VERSION ""

NS_ :

BS_:

BU_:
VAL_TABLE_ DomainCtrl_EPO 1 "急停拍下" 0 "急停恢复" ;
VAL_TABLE_ EPB_FKDSts 1 "锁死" 0 "释放" ;
VAL_TABLE_ EPB2_FAULT 16 "未知状态" 4 "ECU故障" 2 "左卡钳故障" 1 "右卡钳故障" 0 "无故障" ;
VAL_TABLE_ EPB1_FAULT 16 "未知状态" 8 "通讯故障" 4 "ECU故障" 2 "左卡钳故障" 1 "右卡钳故障" 0 "无故障" ;
VAL_TABLE_ EPB_MRSts 4 "unknown" 3 "Applying" 2 "Releasing" 1 "Applied" 0 "Released" ;
VAL_TABLE_ EPB_MLSts 4 "unknown" 3 "Applying" 2 "Releasing" 1 "Applied" 0 "Released" ;
VAL_TABLE_ EPB_RFRSts 4 "unknown" 3 "Applying" 2 "Releasing" 1 "Applied" 0 "Released" ;
VAL_TABLE_ EPB_LFRSts 4 "unknown" 3 "Applying" 2 "Releasing" 1 "Applied" 0 "Released" ;
VAL_TABLE_ SteeringMode 1 "原地掉头" 0 "阿克曼转向" ;
VAL_TABLE_ EBS2_Fault 1 "故障" 0 "正常" ;
VAL_TABLE_ EBS1_Fault 1 "故障" 0 "正常" ;
VAL_TABLE_ RRMCU_Fault 1 "故障" 0 "正常" ;
VAL_TABLE_ RLMCU_Fault 1 "故障" 0 "正常" ;
VAL_TABLE_ MRMCU_Fault 1 "故障" 0 "正常" ;
VAL_TABLE_ MLMCU_Fault 1 "故障" 0 "正常" ;
VAL_TABLE_ FRMCU_Fault 1 "故障" 0 "正常" ;
VAL_TABLE_ FLMCU_Fault 1 "故障" 0 "正常" ;
VAL_TABLE_ CarStartState 2 "关机" 1 "启动" 0 "未知" ;
VAL_TABLE_ CarSts2 1 "急停状态" 0 "READY" ;
VAL_TABLE_ CarSts1 3 "三级报警" 2 "二级报警" 1 "一级报警" 0 "正常" ;
VAL_TABLE_ YK_F 1 "触发" 0 "未触发" ;
VAL_TABLE_ YK_H 1 "触发" 0 "未触发" ;
VAL_TABLE_ EPOSts 2 "硬线触发" 1 "遥控器触发" 0 "未触发" ;
VAL_TABLE_ Gear 3 "D档" 2 "N档" 1 "倒挡R" 0 "P档" ;
VAL_TABLE_ Drive_Mode 2 "遥控器调试模式" 1 "自动模式（线控）" 0 "手动控制模式（油门踏板+挡位）" ;
VAL_TABLE_ OutLineLamp 1 "打开" 0 "关闭" ;
VAL_TABLE_ AlarmLamp 1 "打开" 0 "关闭" ;
VAL_TABLE_ Car_OFF 1 "关机" 0 "正常" ;
VAL_TABLE_ Horn 1 "打开" 0 "关闭" ;
VAL_TABLE_ FarLamp 1 "打开" 0 "关闭" ;
VAL_TABLE_ TurnLamp 2 "右转向" 1 "左转向" 0 "归位" ;
VAL_TABLE_ DippedLamp 1 "打开" 0 "关闭" ;
VAL_TABLE_ Brake_En 1 "使能" 0 "未使能" ;
VAL_TABLE_ Target_Gear 3 "D档" 2 "N档" 1 "倒挡R" 0 "P档" ;
VAL_TABLE_ IPC_En 1 "使能" 0 "未使能" ;
VAL_TABLE_ Ultrasonic_En 1 "关闭" 0 "开启" ;

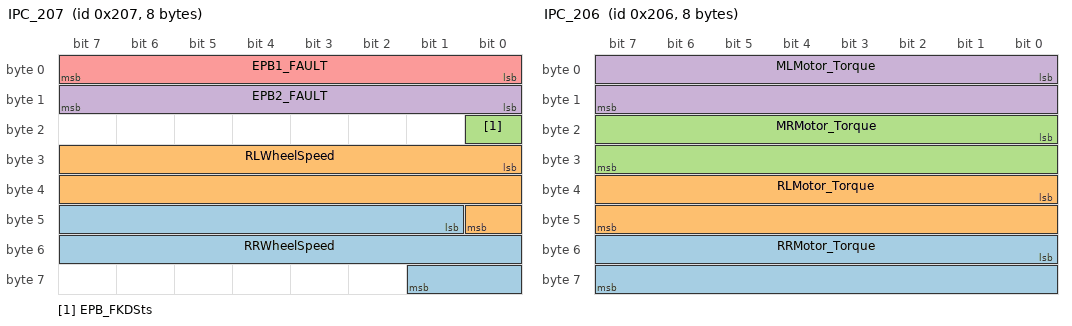
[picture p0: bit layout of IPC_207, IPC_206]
BO_ 519 IPC_207: 8 Vector__XXX
 SG_ RRWheelSpeed : 41|17@1+ (0.01,-655) [-655|655.71] "rpm" Vector__XXX
 SG_ RLWheelSpeed : 24|17@1+ (0.01,-655) [-655|655.71] "rpm" Vector__XXX
 SG_ EPB_FKDSts : 16|1@1+ (1,0) [0|1] "" Vector__XXX
 SG_ EPB2_FAULT : 8|8@1+ (1,0) [0|255] "" Vector__XXX
 SG_ EPB1_FAULT : 0|8@1+ (1,0) [0|255] "" Vector__XXX

BO_ 518 IPC_206: 8 Vector__XXX
 SG_ RRMotor_Torque : 48|16@1+ (0.1,-2000) [-2000|4553.5] "n*m" Vector__XXX
 SG_ RLMotor_Torque : 32|16@1+ (0.1,-2000) [-2000|4553.5] "n*m" Vector__XXX
 SG_ MRMotor_Torque : 16|16@1+ (0.1,-2000) [-2000|4553.5] "n*m" Vector__XXX
 SG_ MLMotor_Torque : 0|16@1+ (0.1,-2000) [-2000|4553.5] "n*m" Vector__XXX

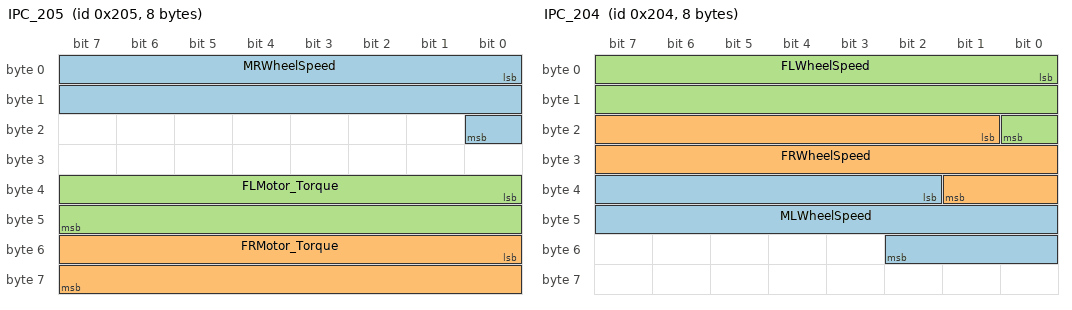
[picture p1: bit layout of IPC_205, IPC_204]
BO_ 517 IPC_205: 8 Vector__XXX
 SG_ MRWheelSpeed : 0|17@1+ (0.01,-655) [-655|655.71] "rpm" Vector__XXX
 SG_ FRMotor_Torque : 48|16@1+ (0.1,-2000) [-2000|4553.5] "n*m" Vector__XXX
 SG_ FLMotor_Torque : 32|16@1+ (0.1,-2000) [-2000|4553.5] "n*m" Vector__XXX

BO_ 516 IPC_204: 8 Vector__XXX
 SG_ MLWheelSpeed : 34|17@1+ (0.01,-655) [-655|655.71] "rpm" Vector__XXX
 SG_ FRWheelSpeed : 17|17@1+ (0.01,-655) [-655|655.71] "rpm" Vector__XXX
 SG_ FLWheelSpeed : 0|17@1+ (0.01,-655) [-655|655.71] "rpm" Vector__XXX

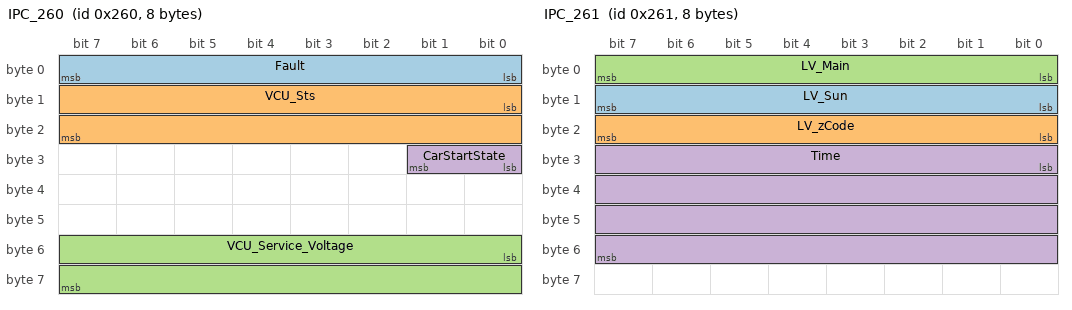
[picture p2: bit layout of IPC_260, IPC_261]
BO_ 608 IPC_260: 8 Vector__XXX
 SG_ Fault : 0|8@1+ (1,0) [0|255] "" Vector__XXX
 SG_ VCU_Sts : 8|16@1+ (1,0) [0|65535] "" Vector__XXX
 SG_ VCU_Service_Voltage : 48|16@1+ (1,0) [0|65535] "mv" Vector__XXX
 SG_ CarStartState : 24|2@1+ (1,0) [0|3] "" Vector__XXX

BO_ 609 IPC_261: 8 Vector__XXX
 SG_ LV_Sun : 8|8@1+ (1,0) [0|255] "" Vector__XXX
 SG_ LV_zCode : 16|8@1+ (1,0) [0|255] "" Vector__XXX
 SG_ LV_Main : 0|8@1+ (1,0) [0|255] "" Vector__XXX
 SG_ Time : 24|32@1+ (1,0) [0|4294967295] "" Vector__XXX

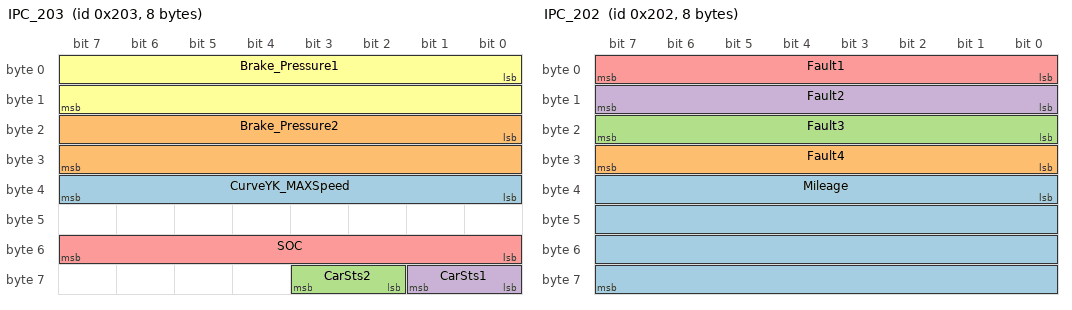
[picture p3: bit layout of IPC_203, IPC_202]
BO_ 515 IPC_203: 8 Vector__XXX
 SG_ CurveYK_MAXSpeed : 32|8@1+ (1,0) [0|255] "km/h" Vector__XXX
 SG_ Brake_Pressure2 : 16|16@1+ (0.05,0) [0|10] "Mpa" Vector__XXX
 SG_ CarSts2 : 58|2@1+ (1,0) [0|3] "" Vector__XXX
 SG_ CarSts1 : 56|2@1+ (1,0) [0|3] "" Vector__XXX
 SG_ SOC : 48|8@1+ (1,0) [0|255] "%" Vector__XXX
 SG_ Brake_Pressure1 : 0|16@1+ (0.05,0) [0|10] "MPa" Vector__XXX

BO_ 514 IPC_202: 8 Vector__XXX
 SG_ Mileage : 32|32@1+ (0.1,0) [0|999999.9] "km" Vector__XXX
 SG_ Fault4 : 24|8@1+ (1,0) [0|255] "" Vector__XXX
 SG_ Fault3 : 16|8@1+ (1,0) [0|255] "" Vector__XXX
 SG_ Fault2 : 8|8@1+ (1,0) [0|255] "" Vector__XXX
 SG_ Fault1 : 0|8@1+ (1,0) [0|255] "" Vector__XXX

BO_ 513 IPC_201: 8 Vector__XXX
 SG_ EPB_MRSts : 60|4@1+ (1,0) [0|15] "" Vector__XXX
 SG_ EPB_MLSts : 56|4@1+ (1,0) [0|15] "" Vector__XXX
 SG_ EPB_RFRSts : 52|4@1+ (1,0) [0|15] "" Vector__XXX
 SG_ EPB_LFRSts : 48|4@1+ (1,0) [0|15] "" Vector__XXX
 SG_ EBS2_Fault : 31|1@1+ (1,0) [0|1] "" Vector__XXX
 SG_ EBS1_Fault : 30|1@1+ (1,0) [0|1] "" Vector__XXX
 SG_ RRMCU_Fault : 29|1@1+ (1,0) [0|1] "" Vector__XXX
 SG_ RLMCU_Fault : 28|1@1+ (1,0) [0|1] "" Vector__XXX
 SG_ MRMCU_Fault : 27|1@1+ (1,0) [0|1] "" Vector__XXX
 SG_ MLMCU_Fault : 26|1@1+ (1,0) [0|1] "" Vector__XXX
 SG_ FRMCU_Fault : 25|1@1+ (1,0) [0|1] "" Vector__XXX
 SG_ FLMCU_Fatus : 24|1@1+ (1,0) [0|1] "" Vector__XXX
 SG_ YK_H : 6|1@1+ (1,0) [0|1] "" Vector__XXX
 SG_ YK_F : 7|1@1+ (1,0) [0|1] "" Vector__XXX
 SG_ Car_Speed : 32|16@1+ (0.1,0) [0|6553.5] "km/h" Vector__XXX
 SG_ Gear : 2|2@1+ (1,0) [0|3] "" Vector__XXX
 SG_ EPOSts : 4|2@1+ (1,0) [0|3] "" Vector__XXX
 SG_ Drive_Mode : 0|2@1+ (1,0) [0|3] "" Vector__XXX
 SG_ Angle : 8|16@1- (1,0) [-32768|32767] "°" Vector__XXX

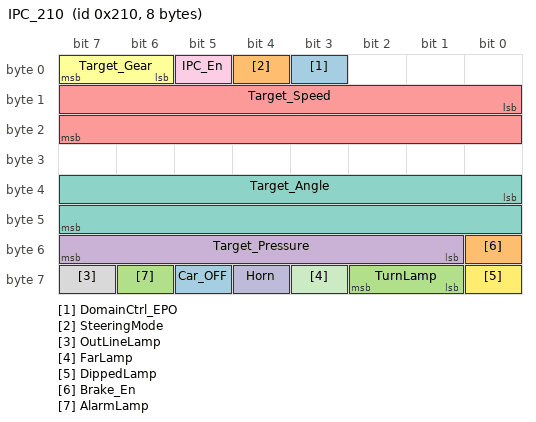
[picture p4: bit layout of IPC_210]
BO_ 528 IPC_210: 8 Vector__XXX
 SG_ DomainCtrl_EPO : 3|1@1+ (1,0) [0|1] "" Vector__XXX
 SG_ SteeringMode : 4|1@1+ (1,0) [0|1] "" Vector__XXX
 SG_ TurnLamp : 57|2@1+ (1,0) [0|3] "" Vector__XXX
 SG_ Target_Pressure : 49|7@1+ (0.1,0) [0|6] "Mpa" Vector__XXX
 SG_ Target_Speed : 8|16@1+ (0.1,0) [0|6553.5] "km/h" Vector__XXX
 SG_ Target_Gear : 6|2@1+ (1,0) [0|3] "" Vector__XXX
 SG_ Target_Angle : 32|16@1- (1,0) [-32768|32767] "°" Vector__XXX
 SG_ OutLineLamp : 63|1@1+ (1,0) [0|1] "" Vector__XXX
 SG_ IPC_En : 5|1@1+ (1,0) [0|1] "" Vector__XXX
 SG_ Horn : 60|1@1+ (1,0) [0|1] "" Vector__XXX
 SG_ FarLamp : 59|1@1+ (1,0) [0|1] "" Vector__XXX
 SG_ DippedLamp : 56|1@1+ (1,0) [0|1] "" Vector__XXX
 SG_ Car_OFF : 61|1@1+ (1,0) [0|1] "" Vector__XXX
 SG_ Brake_En : 48|1@1+ (1,0) [0|1] "" Vector__XXX
 SG_ AlarmLamp : 62|1@1+ (1,0) [0|1] "" Vector__XXX

CM_ SG_ 519 RRWheelSpeed "右后车轮转速";
CM_ SG_ 519 RLWheelSpeed "左后车轮转速";
CM_ SG_ 519 EPB_FKDSts "EPS反馈状态遥控读取";
CM_ SG_ 519 EPB2_FAULT "EPB左中轮系统故障";
CM_ SG_ 519 EPB1_FAULT "EPB左前左后轮系统故障";
CM_ SG_ 518 RRMotor_Torque "右后电机扭矩";
CM_ SG_ 518 RLMotor_Torque "左后电机扭矩";
CM_ SG_ 518 MRMotor_Torque "右中电机扭矩";
CM_ SG_ 518 MLMotor_Torque "左中电机扭矩";
CM_ SG_ 517 MRWheelSpeed "右中轮速转速";
CM_ SG_ 517 FRMotor_Torque "右前电机扭矩";
CM_ SG_ 517 FLMotor_Torque "左前电机扭矩
";
CM_ SG_ 516 MLWheelSpeed "左中轮速转速";
CM_ SG_ 516 FRWheelSpeed "右前轮速转速";
CM_ SG_ 516 FLWheelSpeed "左前轮速转速";
CM_ SG_ 608 Fault "整车故障";
CM_ SG_ 608 VCU_Sts "VCU状态	";
CM_ SG_ 608 VCU_Service_Voltage "VCU供电电压";
CM_ SG_ 608 CarStartState "车辆启动状态
VCU状态标识等于2/3/5时开机，否则关机
";
CM_ SG_ 609 LV_Sun "子版本";
CM_ SG_ 609 LV_zCode "修订版本";
CM_ SG_ 609 LV_Main "主版本";
CM_ SG_ 609 Time "日期";
CM_ SG_ 515 CurveYK_MAXSpeed "当前遥控油门推杆的最高车速";
CM_ SG_ 515 CarSts2 "车辆状态2	
";
CM_ SG_ 515 CarSts1 "车辆状态1	
";
CM_ SG_ 515 SOC "电池电量
";
CM_ SG_ 515 Brake_Pressure1 "制动压力
";
CM_ SG_ 514 Mileage "里程
";
CM_ SG_ 514 Fault4 "故障代码4	
	
";
CM_ SG_ 514 Fault3 "故障代码3	
	
";
CM_ SG_ 514 Fault2 "故障代码2	
	
";
CM_ SG_ 514 Fault1 "故障代码1	
	
";
CM_ SG_ 513 EPB_MRSts "EPB右中轮状态反馈";
CM_ SG_ 513 EPB_MLSts "EPB左中轮状态反馈";
CM_ SG_ 513 EPB_RFRSts "EPB右前轮和右后轮状态反馈";
CM_ SG_ 513 EPB_LFRSts "EPB左前轮和左后轮状态反馈";
CM_ SG_ 513 EBS2_Fault "制动CAN3故障";
CM_ SG_ 513 EBS1_Fault "制动CAN1故障";
CM_ SG_ 513 RRMCU_Fault "右后电机故障";
CM_ SG_ 513 RLMCU_Fault "左后电机故障";
CM_ SG_ 513 MRMCU_Fault "右中电机故障";
CM_ SG_ 513 MLMCU_Fault "左中电机故障";
CM_ SG_ 513 FRMCU_Fault "右前电机故障";
CM_ SG_ 513 FLMCU_Fatus "左前电机故障";
CM_ SG_ 513 YK_H "遥控键H
";
CM_ SG_ 513 YK_F "遥控F键
";
CM_ SG_ 513 Car_Speed "当前车速
";
CM_ SG_ 513 Gear "挡位
";
CM_ SG_ 513 EPOSts "急停状态
";
CM_ SG_ 513 Drive_Mode "驾驶模式
";
CM_ SG_ 513 Angle "当前角度
";
CM_ SG_ 528 DomainCtrl_EPO "域控急停";
CM_ SG_ 528 SteeringMode "转向模式";
CM_ SG_ 528 TurnLamp "转向灯
";
CM_ SG_ 528 Target_Pressure "目标压力
";
CM_ SG_ 528 Target_Speed "目标车速
";
CM_ SG_ 528 Target_Gear "目标挡位
";
CM_ SG_ 528 Target_Angle "目标角度
";
CM_ SG_ 528 OutLineLamp "轮廓灯（小灯）
";
CM_ SG_ 528 IPC_En "控制使能
";
CM_ SG_ 528 Horn "喇叭
";
CM_ SG_ 528 FarLamp "远光灯
";
CM_ SG_ 528 DippedLamp "近光
";
CM_ SG_ 528 Car_OFF "关机
";
CM_ SG_ 528 Brake_En "制动使能";
CM_ SG_ 528 AlarmLamp "双闪（App接入）";
BA_DEF_ SG_  "GenSigSendType" ENUM  "Cyclic","OnWrite","OnWriteWithRepetition","OnChange","OnChangeWithRepetition","IfActive","IfActiveWithRepetition","NoSigSendType";
BA_DEF_ BO_  "GenMsgSendType" ENUM  "Cyclic","not_used","not_used","not_used","not_used","Cyclic","not_used","IfActive","NoMsgSendType";
BA_DEF_  "DBName" STRING ;
BA_DEF_  "BusType" STRING ;
BA_DEF_DEF_  "GenSigSendType" "Cyclic";
BA_DEF_DEF_  "GenMsgSendType" "NoMsgSendType";
BA_DEF_DEF_  "DBName" "";
BA_DEF_DEF_  "BusType" "CAN";
BA_ "DBName" "IPC_VCU";
VAL_ 519 EPB_FKDSts 1 "锁死" 0 "释放" ;
VAL_ 519 EPB2_FAULT 16 "未知状态" 4 "ECU故障" 2 "左卡钳故障" 1 "右卡钳故障" 0 "无故障" ;
VAL_ 519 EPB1_FAULT 16 "未知状态" 8 "通讯故障" 4 "ECU故障" 2 "左卡钳故障" 1 "右卡钳故障" 0 "无故障" ;
VAL_ 608 CarStartState 2 "关机" 1 "启动" 0 "未知" ;
VAL_ 515 CarSts2 1 "急停状态" 0 "READY" ;
VAL_ 515 CarSts1 3 "三级报警" 2 "二级报警" 1 "一级报警" 0 "正常" ;
VAL_ 513 EPB_MRSts 4 "unknown" 3 "Applying" 2 "Releasing" 1 "Applied" 0 "Released" ;
VAL_ 513 EPB_MLSts 4 "unknown" 3 "Applying" 2 "Releasing" 1 "Applied" 0 "Released" ;
VAL_ 513 EPB_RFRSts 4 "unknown" 3 "Applying" 2 "Releasing" 1 "Applied" 0 "Released" ;
VAL_ 513 EPB_LFRSts 4 "unknown" 3 "Applying" 2 "Releasing" 1 "Applied" 0 "Released" ;
VAL_ 513 EBS2_Fault 1 "故障" 0 "正常" ;
VAL_ 513 EBS1_Fault 1 "故障" 0 "正常" ;
VAL_ 513 RRMCU_Fault 1 "故障" 0 "正常" ;
VAL_ 513 RLMCU_Fault 1 "故障" 0 "正常" ;
VAL_ 513 MRMCU_Fault 1 "故障" 0 "正常" ;
VAL_ 513 MLMCU_Fault 1 "故障" 0 "正常" ;
VAL_ 513 FRMCU_Fault 1 "故障" 0 "正常" ;
VAL_ 513 FLMCU_Fatus 1 "故障" 0 "正常" ;
VAL_ 513 YK_H 1 "触发" 0 "未触发" ;
VAL_ 513 YK_F 1 "触发" 0 "未触发" ;
VAL_ 513 Gear 3 "D档" 2 "N档" 1 "倒挡R" 0 "P档" ;
VAL_ 513 EPOSts 2 "硬线触发" 1 "遥控器触发" 0 "未触发" ;
VAL_ 513 Drive_Mode 2 "遥控器调试模式" 1 "自动模式（线控）" 0 "手动控制模式（油门踏板+挡位）" ;
VAL_ 528 DomainCtrl_EPO 1 "急停拍下" 0 "急停恢复" ;
VAL_ 528 SteeringMode 1 "原地掉头" 0 "阿克曼转向" ;
VAL_ 528 TurnLamp 2 "右转向" 1 "左转向" 0 "归位" ;
VAL_ 528 Target_Gear 3 "D档" 2 "N档" 1 "倒挡R" 0 "P档" ;
VAL_ 528 OutLineLamp 1 "打开" 0 "关闭" ;
VAL_ 528 IPC_En 1 "使能" 0 "未使能" ;
VAL_ 528 Horn 1 "打开" 0 "关闭" ;
VAL_ 528 FarLamp 1 "打开" 0 "关闭" ;
VAL_ 528 DippedLamp 1 "打开" 0 "关闭" ;
VAL_ 528 Car_OFF 1 "关机" 0 "正常" ;
VAL_ 528 Brake_En 1 "使能" 0 "未使能" ;
VAL_ 528 AlarmLamp 1 "打开" 0 "关闭" ;
